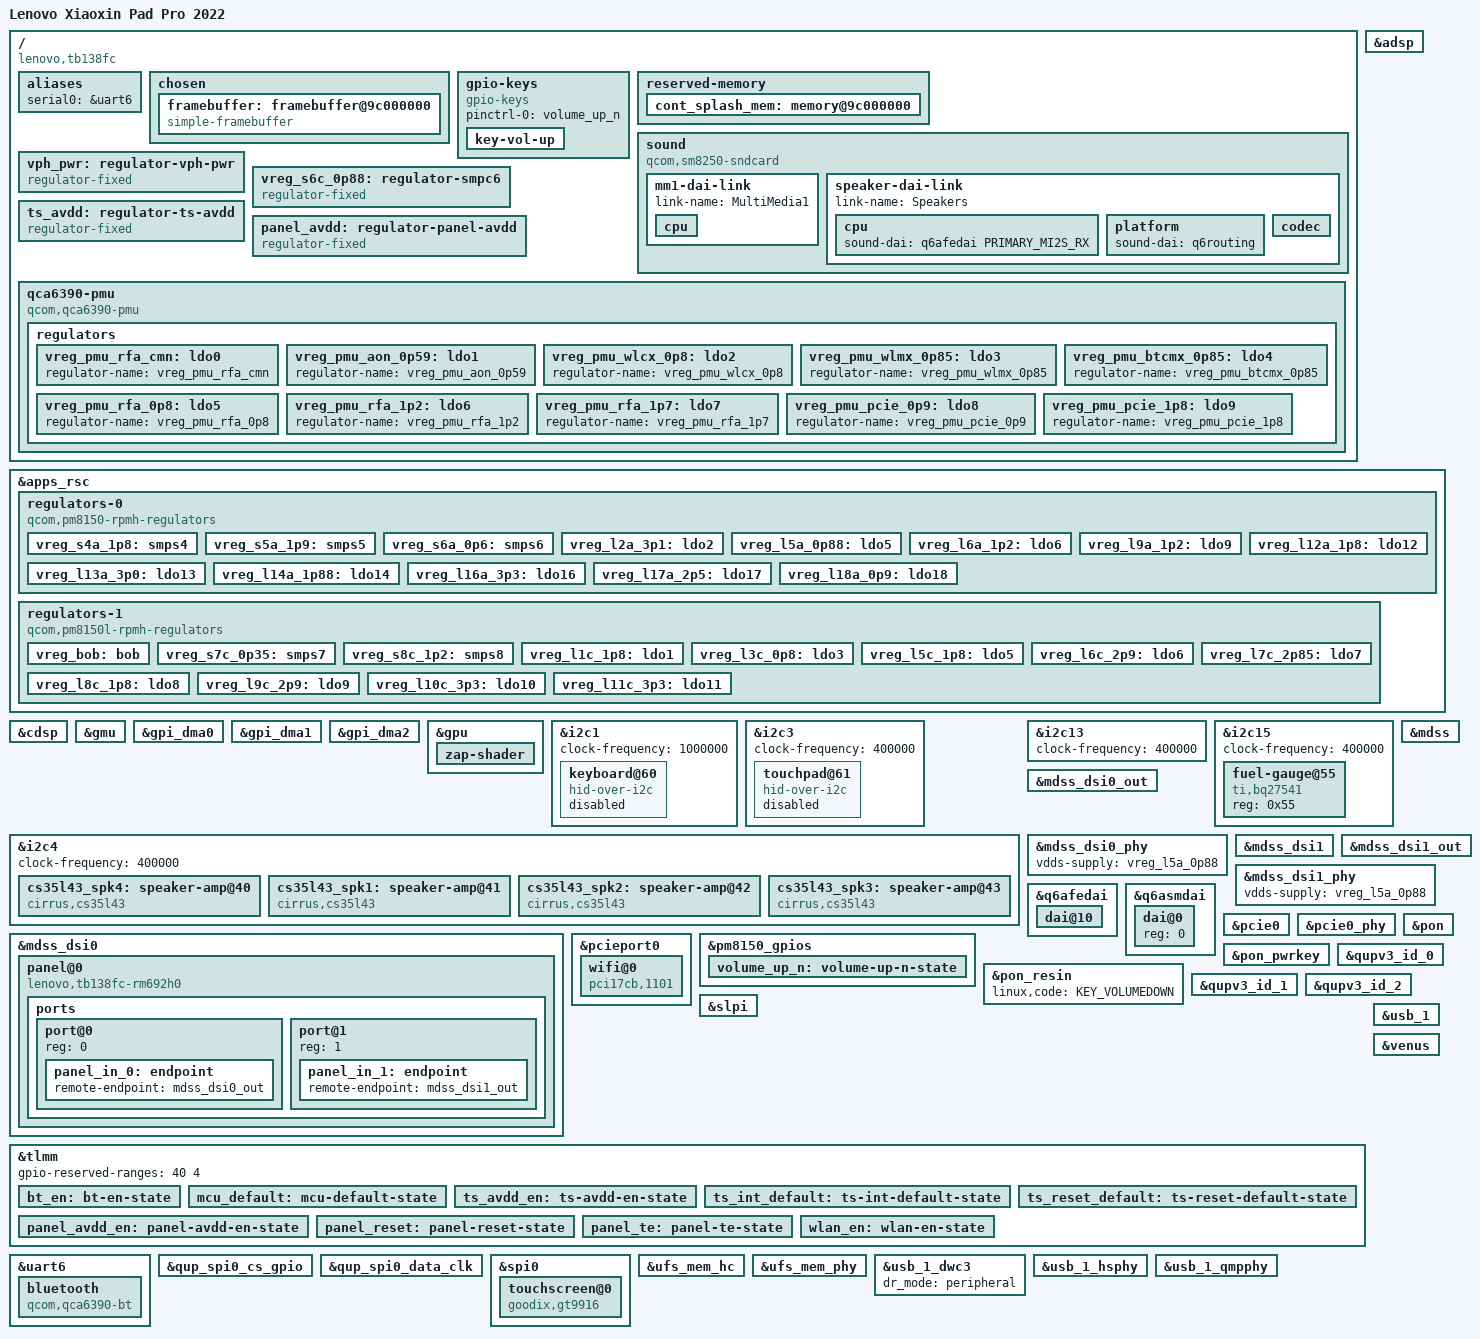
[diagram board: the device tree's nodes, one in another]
// SPDX-License-Identifier: GPL-2.0-only
/*
 * Copyright (c) 2025, David Wronek (sm8250-lenovo-j716f.dts)
 *
 * Lenovo Xiaoxin Pad Pro 2022 (TB138FC), derived from the J716F devicetree.
 * Initial bring-up: UFS, USB (peripheral), simple-framebuffer, buttons, fuel gauge.
 */

/dts-v1/;

#include <dt-bindings/arm/qcom,ids.h>
#include <dt-bindings/gpio/gpio.h>
#include <dt-bindings/phy/phy.h>
#include <dt-bindings/regulator/qcom,rpmh-regulator.h>
#include <dt-bindings/sound/qcom,q6afe.h>
#include <dt-bindings/sound/qcom,q6asm.h>
#include "sm8250.dtsi"
#include "pm8150.dtsi"
#include "pm8150l.dtsi"

/ {
	model = "Lenovo Xiaoxin Pad Pro 2022";
	compatible = "lenovo,tb138fc", "qcom,sm8250";
	chassis-type = "tablet";

	/* required for bootloader to select correct board */
	qcom,msm-id = <QCOM_ID_SM8250 0x20001>; /* SM8250 v2.1 */
	qcom,board-id = <0x10008 0>, <0x2010008 0>, <0x3010008 0>;

	aliases {
		serial0 = &uart6;
	};

	chosen {
		#address-cells = <2>;
		#size-cells = <2>;
		ranges;

		framebuffer: framebuffer@9c000000 {
			compatible = "simple-framebuffer";
			reg = <0x0 0x9c000000 0x0 0x2300000>;
			width = <2560>;
			height = <1536>;
			stride = <(2560 * 4)>;
			format = "a8r8g8b8";
		};
	};

	gpio-keys {
		compatible = "gpio-keys";

		pinctrl-names = "default";
		pinctrl-0 = <&volume_up_n>;

		key-vol-up {
			label = "Volume Up";
			linux,code = <KEY_VOLUMEUP>;
			gpios = <&pm8150_gpios 6 GPIO_ACTIVE_LOW>;
			debounce-interval = <15>;
			linux,can-disable;
			wakeup-source;
		};
	};

	reserved-memory {
		cont_splash_mem: memory@9c000000 {
			reg = <0x0 0x9c000000 0x0 0x2300000>;
			no-map;
		};
	};

	sound {
		compatible = "qcom,sm8250-sndcard";
		model = "Lenovo-TB138FC";
		pinctrl-0 = <&pri_mi2s_active>;
		pinctrl-names = "default";

		mm1-dai-link {
			link-name = "MultiMedia1";

			cpu {
				sound-dai = <&q6asmdai MSM_FRONTEND_DAI_MULTIMEDIA1>;
			};
		};

		speaker-dai-link {
			link-name = "Speakers";

			cpu {
				sound-dai = <&q6afedai PRIMARY_MI2S_RX>;
			};

			platform {
				sound-dai = <&q6routing>;
			};

			codec {
				sound-dai = <&cs35l43_spk1>, <&cs35l43_spk2>,
					    <&cs35l43_spk3>, <&cs35l43_spk4>;
			};
		};
	};

	vph_pwr: regulator-vph-pwr {
		compatible = "regulator-fixed";

		regulator-name = "vph_pwr";
		regulator-min-microvolt = <3700000>;
		regulator-max-microvolt = <3700000>;
		regulator-always-on;
		regulator-boot-on;
	};

	/* S6c is really ebi.lvl but it's there for supply map completeness sake. */
	vreg_s6c_0p88: regulator-smpc6 {
		compatible = "regulator-fixed";

		regulator-name = "vreg_s6c_0p88";
		regulator-min-microvolt = <880000>;
		regulator-max-microvolt = <880000>;
		regulator-always-on;

		vin-supply = <&vph_pwr>;
	};

	ts_avdd: regulator-ts-avdd {
		compatible = "regulator-fixed";
		regulator-name = "ts_avdd";
		regulator-min-microvolt = <3300000>;
		regulator-max-microvolt = <3300000>;

		gpio = <&tlmm 108 GPIO_ACTIVE_HIGH>;
		enable-active-high;
		startup-delay-us = <10000>;

		pinctrl-names = "default";
		pinctrl-0 = <&ts_avdd_en>;
	};

	panel_avdd: regulator-panel-avdd {
		compatible = "regulator-fixed";
		regulator-name = "panel_avdd";
		regulator-min-microvolt = <5500000>;
		regulator-max-microvolt = <5500000>;

		gpio = <&tlmm 61 GPIO_ACTIVE_HIGH>;
		enable-active-high;
		regulator-boot-on;

		pinctrl-names = "default";
		pinctrl-0 = <&panel_avdd_en>;
	};

	qca6390-pmu {
		compatible = "qcom,qca6390-pmu";

		pinctrl-names = "default";
		pinctrl-0 = <&bt_en>, <&wlan_en>;

		vddaon-supply = <&vreg_s6a_0p6>;
		vddpmu-supply = <&vreg_s6a_0p6>;
		vddrfa0p95-supply = <&vreg_s6a_0p6>;
		vddrfa1p3-supply = <&vreg_s8c_1p2>;
		vddrfa1p9-supply = <&vreg_s5a_1p9>;
		vddpcie1p3-supply = <&vreg_s8c_1p2>;
		vddpcie1p9-supply = <&vreg_s5a_1p9>;
		vddio-supply = <&vreg_s4a_1p8>;

		wlan-enable-gpios = <&tlmm 20 GPIO_ACTIVE_HIGH>;
		bt-enable-gpios = <&tlmm 21 GPIO_ACTIVE_HIGH>;

		regulators {
			vreg_pmu_rfa_cmn: ldo0 {
				regulator-name = "vreg_pmu_rfa_cmn";
			};

			vreg_pmu_aon_0p59: ldo1 {
				regulator-name = "vreg_pmu_aon_0p59";
			};

			vreg_pmu_wlcx_0p8: ldo2 {
				regulator-name = "vreg_pmu_wlcx_0p8";
			};

			vreg_pmu_wlmx_0p85: ldo3 {
				regulator-name = "vreg_pmu_wlmx_0p85";
			};

			vreg_pmu_btcmx_0p85: ldo4 {
				regulator-name = "vreg_pmu_btcmx_0p85";
			};

			vreg_pmu_rfa_0p8: ldo5 {
				regulator-name = "vreg_pmu_rfa_0p8";
			};

			vreg_pmu_rfa_1p2: ldo6 {
				regulator-name = "vreg_pmu_rfa_1p2";
			};

			vreg_pmu_rfa_1p7: ldo7 {
				regulator-name = "vreg_pmu_rfa_1p7";
			};

			vreg_pmu_pcie_0p9: ldo8 {
				regulator-name = "vreg_pmu_pcie_0p9";
			};

			vreg_pmu_pcie_1p8: ldo9 {
				regulator-name = "vreg_pmu_pcie_1p8";
			};
		};
	};
};

&adsp {
	firmware-name = "qcom/sm8250/LENOVO/TB138FC/adsp.mbn";
	status = "okay";
};

&apps_rsc {
	regulators-0 {
		compatible = "qcom,pm8150-rpmh-regulators";
		qcom,pmic-id = "a";

		vdd-s1-supply = <&vph_pwr>;
		vdd-s2-supply = <&vph_pwr>;
		vdd-s3-supply = <&vph_pwr>;
		vdd-s4-supply = <&vph_pwr>;
		vdd-s5-supply = <&vph_pwr>;
		vdd-s6-supply = <&vph_pwr>;
		vdd-s7-supply = <&vph_pwr>;
		vdd-s8-supply = <&vph_pwr>;
		vdd-s9-supply = <&vph_pwr>;
		vdd-s10-supply = <&vph_pwr>;
		vdd-l1-l8-l11-supply = <&vreg_s6c_0p88>;
		vdd-l2-l10-supply = <&vreg_bob>;
		vdd-l3-l4-l5-l18-supply = <&vreg_s6a_0p6>;
		vdd-l6-l9-supply = <&vreg_s8c_1p2>;
		vdd-l7-l12-l14-l15-supply = <&vreg_s5a_1p9>;
		vdd-l13-l16-l17-supply = <&vreg_bob>;

		/* (S1+S2+S3) - cx.lvl (ARC) */

		vreg_s4a_1p8: smps4 {
			regulator-name = "vreg_s4a_1p8";
			regulator-min-microvolt = <1800000>;
			regulator-max-microvolt = <1920000>;
			regulator-initial-mode = <RPMH_REGULATOR_MODE_HPM>;
			regulator-allow-set-load;
			regulator-allowed-modes = <RPMH_REGULATOR_MODE_LPM
						   RPMH_REGULATOR_MODE_HPM>;
		};

		vreg_s5a_1p9: smps5 {
			regulator-name = "vreg_s5a_1p9";
			regulator-min-microvolt = <1900000>;
			regulator-max-microvolt = <2040000>;
			regulator-initial-mode = <RPMH_REGULATOR_MODE_HPM>;
		};

		vreg_s6a_0p6: smps6 {
			regulator-name = "vreg_s6a_0p6";
			regulator-min-microvolt = <600000>;
			regulator-max-microvolt = <1128000>;
			regulator-initial-mode = <RPMH_REGULATOR_MODE_HPM>;
		};

		vreg_l2a_3p1: ldo2 {
			regulator-name = "vreg_l2a_3p1";
			regulator-min-microvolt = <3072000>;
			regulator-max-microvolt = <3072000>;
			regulator-initial-mode = <RPMH_REGULATOR_MODE_HPM>;
		};

		/* L3 is unused, L4 - lmx.lvl (ARC) */

		vreg_l5a_0p88: ldo5 {
			regulator-name = "vreg_l5a_0p88";
			regulator-min-microvolt = <880000>;
			regulator-max-microvolt = <880000>;
			regulator-initial-mode = <RPMH_REGULATOR_MODE_HPM>;
		};

		vreg_l6a_1p2: ldo6 {
			regulator-name = "vreg_l6a_1p2";
			regulator-min-microvolt = <1200000>;
			regulator-max-microvolt = <1200000>;
			regulator-initial-mode = <RPMH_REGULATOR_MODE_HPM>;
			regulator-allow-set-load;
			regulator-allowed-modes = <RPMH_REGULATOR_MODE_LPM
						   RPMH_REGULATOR_MODE_HPM>;
		};

		/* L7 is unused. */

		vreg_l9a_1p2: ldo9 {
			regulator-name = "vreg_l9a_1p2";
			regulator-min-microvolt = <1200000>;
			regulator-max-microvolt = <1200000>;
			regulator-initial-mode = <RPMH_REGULATOR_MODE_HPM>;
		};

		/* L10 is unused, L11 - lcx.lvl (ARC) */

		vreg_l12a_1p8: ldo12 {
			regulator-name = "vreg_l12a_1p8";
			regulator-min-microvolt = <1800000>;
			regulator-max-microvolt = <1800000>;
			regulator-initial-mode = <RPMH_REGULATOR_MODE_HPM>;
		};

		vreg_l13a_3p0: ldo13 {
			regulator-name = "vreg_l13a_3p0";
			regulator-min-microvolt = <3008000>;
			regulator-max-microvolt = <3008000>;
			regulator-initial-mode = <RPMH_REGULATOR_MODE_HPM>;
		};

		vreg_l14a_1p88: ldo14 {
			regulator-name = "vreg_l14a_1p88";
			regulator-min-microvolt = <1800000>;
			regulator-max-microvolt = <1880000>;
			regulator-initial-mode = <RPMH_REGULATOR_MODE_HPM>;
		};

		/* L15 is unused. */

		vreg_l16a_3p3: ldo16 {
			regulator-name = "vreg_l16a_3p3";
			regulator-min-microvolt = <3024000>;
			regulator-max-microvolt = <3304000>;
			regulator-initial-mode = <RPMH_REGULATOR_MODE_HPM>;
		};

		vreg_l17a_2p5: ldo17 {
			regulator-name = "vreg_l17a_2p5";
			regulator-min-microvolt = <2496000>;
			regulator-max-microvolt = <3008000>;
			regulator-initial-mode = <RPMH_REGULATOR_MODE_HPM>;
			regulator-allow-set-load;
			regulator-allowed-modes = <RPMH_REGULATOR_MODE_LPM
						   RPMH_REGULATOR_MODE_HPM>;
		};

		vreg_l18a_0p9: ldo18 {
			regulator-name = "vreg_l18a_0p9";
			regulator-min-microvolt = <800000>;
			regulator-max-microvolt = <920000>;
			regulator-initial-mode = <RPMH_REGULATOR_MODE_HPM>;
		};
	};

	/*
	 * Remaining regulators that are not yet supported:
	 * OLEDB: 4925000-8100000
	 * ab: 4600000-6100000
	 * ibb: 800000-5400000
	 */

	regulators-1 {
		compatible = "qcom,pm8150l-rpmh-regulators";
		qcom,pmic-id = "c";

		vdd-s1-supply = <&vph_pwr>;
		vdd-s2-supply = <&vph_pwr>;
		vdd-s3-supply = <&vph_pwr>;
		vdd-s4-supply = <&vph_pwr>;
		vdd-s5-supply = <&vph_pwr>;
		vdd-s6-supply = <&vph_pwr>;
		vdd-s7-supply = <&vph_pwr>;
		vdd-s8-supply = <&vph_pwr>;
		vdd-l1-l8-supply = <&vreg_s4a_1p8>;
		vdd-l2-l3-supply = <&vreg_s8c_1p2>;
		vdd-l4-l5-l6-supply = <&vreg_bob>;
		vdd-l7-l11-supply = <&vreg_bob>;
		vdd-l9-l10-supply = <&vreg_bob>;
		vdd-bob-supply = <&vph_pwr>;

		vreg_bob: bob {
			regulator-name = "vreg_bob";
			regulator-min-microvolt = <3008000>;
			regulator-max-microvolt = <3960000>;
			regulator-initial-mode = <RPMH_REGULATOR_MODE_AUTO>;
		};

		/*
		 * S1-S6 are ARCs:
		 * (S1+S2) - gfx.lvl,
		 * S3 - mx.lvl,
		 * (S4+S5) - mmcx.lvl,
		 * S6 - ebi.lvl
		 */

		vreg_s7c_0p35: smps7 {
			regulator-name = "vreg_s7c_0p35";
			regulator-min-microvolt = <348000>;
			regulator-max-microvolt = <1000000>;
			regulator-initial-mode = <RPMH_REGULATOR_MODE_HPM>;
		};

		vreg_s8c_1p2: smps8 {
			regulator-name = "vreg_s8c_1p2";
			regulator-min-microvolt = <1200000>;
			regulator-max-microvolt = <1400000>;
			regulator-initial-mode = <RPMH_REGULATOR_MODE_HPM>;
		};

		vreg_l1c_1p8: ldo1 {
			regulator-name = "vreg_l1c_1p8";
			regulator-min-microvolt = <1800000>;
			regulator-max-microvolt = <1800000>;
			regulator-initial-mode = <RPMH_REGULATOR_MODE_HPM>;
		};

		/* L2 is unused. */

		vreg_l3c_0p8: ldo3 {
			regulator-name = "vreg_l3c_0p8";
			regulator-min-microvolt = <800000>;
			regulator-max-microvolt = <1200000>;
			regulator-initial-mode = <RPMH_REGULATOR_MODE_HPM>;
		};

		/* L4 is unused. */

		vreg_l5c_1p8: ldo5 {
			regulator-name = "vreg_l5c_1p8";
			regulator-min-microvolt = <1800000>;
			regulator-max-microvolt = <2800000>;
			regulator-initial-mode = <RPMH_REGULATOR_MODE_HPM>;
		};

		vreg_l6c_2p9: ldo6 {
			regulator-name = "vreg_l6c_2p9";
			regulator-min-microvolt = <1800000>;
			regulator-max-microvolt = <2960000>;
			regulator-initial-mode = <RPMH_REGULATOR_MODE_HPM>;
			regulator-allow-set-load;
			regulator-allowed-modes = <RPMH_REGULATOR_MODE_LPM
						   RPMH_REGULATOR_MODE_HPM>;
		};

		vreg_l7c_2p85: ldo7 {
			regulator-name = "vreg_l7c_2p85";
			regulator-min-microvolt = <2856000>;
			regulator-max-microvolt = <3104000>;
			regulator-initial-mode = <RPMH_REGULATOR_MODE_HPM>;
		};

		vreg_l8c_1p8: ldo8 {
			regulator-name = "vreg_l8c_1p8";
			regulator-min-microvolt = <1800000>;
			regulator-max-microvolt = <1800000>;
			regulator-initial-mode = <RPMH_REGULATOR_MODE_HPM>;
		};

		vreg_l9c_2p9: ldo9 {
			regulator-name = "vreg_l9c_2p9";
			regulator-min-microvolt = <2704000>;
			regulator-max-microvolt = <2960000>;
			regulator-initial-mode = <RPMH_REGULATOR_MODE_HPM>;
			regulator-allow-set-load;
			regulator-allowed-modes = <RPMH_REGULATOR_MODE_LPM
						   RPMH_REGULATOR_MODE_HPM>;
		};

		vreg_l10c_3p3: ldo10 {
			regulator-name = "vreg_l10c_3p3";
			regulator-min-microvolt = <3000000>;
			regulator-max-microvolt = <3312000>;
			regulator-initial-mode = <RPMH_REGULATOR_MODE_HPM>;
		};

		vreg_l11c_3p3: ldo11 {
			regulator-name = "vreg_l11c_3p3";
			regulator-min-microvolt = <3300000>;	/* panel vdd: stock 3.3 V */
			regulator-max-microvolt = <3304000>;
			regulator-initial-mode = <RPMH_REGULATOR_MODE_HPM>;
		};
	};

};

&cdsp {
	firmware-name = "qcom/sm8250/LENOVO/TB138FC/cdsp.mbn";
	status = "okay";
};

&gmu {
	status = "okay";
};

&gpi_dma0 {
	status = "okay";
};

&gpi_dma1 {
	status = "okay";
};

&gpi_dma2 {
	status = "okay";
};

&gpu {
	status = "okay";

	zap-shader {
		memory-region = <&gpu_mem>;
		firmware-name = "qcom/sm8250/LENOVO/TB138FC/a650_zap.mbn";
	};
};

&i2c1 {
	clock-frequency = <1000000>;
	status = "okay";

	/* Stock: keyboard@60, irqs on gpio54/gpio129; not yet verified */
	keyboard@60 {
		compatible = "hid-over-i2c";
		reg = <0x60>;

		vdd-supply = <&vreg_l16a_3p3>;
		vddl-supply = <&vreg_l8c_1p8>;

		interrupt-parent = <&tlmm>;
		interrupts = <54 IRQ_TYPE_LEVEL_LOW>;

		hid-descr-addr = <0x01>;
		post-power-on-delay-ms = <100>;
		status = "disabled";
	};
};

&i2c3 {
	clock-frequency = <400000>;
	status = "okay";

	/* Stock: keyboard-pack touchpad, irq on gpio11; not yet verified */
	touchpad@61 {
		compatible = "hid-over-i2c";
		reg = <0x61>;

		vdd-supply = <&vreg_l16a_3p3>;
		vddl-supply = <&vreg_l8c_1p8>;

		pinctrl-names = "default";
		pinctrl-0 = <&mcu_default>;

		interrupt-parent = <&tlmm>;
		interrupts = <11 IRQ_TYPE_LEVEL_LOW>;

		hid-descr-addr = <0x01>;
		post-power-on-delay-ms = <100>;
		status = "disabled";
	};
};

&i2c4 {
	clock-frequency = <400000>;
	status = "okay";


	cs35l43_spk4: speaker-amp@40 {
		compatible = "cirrus,cs35l43";
		reg = <0x40>;
		interrupts-extended = <&tlmm 68 IRQ_TYPE_LEVEL_LOW>;
		reset-gpios = <&tlmm 131 GPIO_ACTIVE_HIGH>;
		VA-supply = <&vreg_s4a_1p8>;
		VP-supply = <&vph_pwr>;
		#sound-dai-cells = <0>;
		sound-name-prefix = "SPK4";
		cirrus,dsp-part-name = "spk4-cs35l43";
		cirrus,bst-ipk-ma = <3200>;	/* stock boost-peak-milliamp */
		cirrus,asp-sdout-hiz = <3>;
		cirrus,vpbr-enable = <1>;
		cirrus,vpbr-atk-vol = <2>;
		cirrus,vpbr-max-att = <6>;
		cirrus,vpbr-thld = <21>;
	};

	cs35l43_spk1: speaker-amp@41 {
		compatible = "cirrus,cs35l43";
		reg = <0x41>;
		interrupts-extended = <&tlmm 68 IRQ_TYPE_LEVEL_LOW>;
		reset-gpios = <&tlmm 131 GPIO_ACTIVE_HIGH>;
		VA-supply = <&vreg_s4a_1p8>;
		VP-supply = <&vph_pwr>;
		#sound-dai-cells = <0>;
		sound-name-prefix = "SPK1";
		cirrus,dsp-part-name = "spk1-cs35l43";
		cirrus,bst-ipk-ma = <3200>;	/* stock boost-peak-milliamp */
		cirrus,asp-sdout-hiz = <3>;
		cirrus,vpbr-enable = <1>;
		cirrus,vpbr-atk-vol = <2>;
		cirrus,vpbr-max-att = <6>;
		cirrus,vpbr-thld = <21>;
	};

	cs35l43_spk2: speaker-amp@42 {
		compatible = "cirrus,cs35l43";
		reg = <0x42>;
		interrupts-extended = <&tlmm 68 IRQ_TYPE_LEVEL_LOW>;
		reset-gpios = <&tlmm 131 GPIO_ACTIVE_HIGH>;
		VA-supply = <&vreg_s4a_1p8>;
		VP-supply = <&vph_pwr>;
		#sound-dai-cells = <0>;
		sound-name-prefix = "SPK2";
		cirrus,dsp-part-name = "spk2-cs35l43";
		cirrus,bst-ipk-ma = <3200>;	/* stock boost-peak-milliamp */
		cirrus,asp-sdout-hiz = <3>;
		cirrus,vpbr-enable = <1>;
		cirrus,vpbr-atk-vol = <2>;
		cirrus,vpbr-max-att = <6>;
		cirrus,vpbr-thld = <21>;
	};

	cs35l43_spk3: speaker-amp@43 {
		compatible = "cirrus,cs35l43";
		reg = <0x43>;
		interrupts-extended = <&tlmm 68 IRQ_TYPE_LEVEL_LOW>;
		reset-gpios = <&tlmm 131 GPIO_ACTIVE_HIGH>;
		VA-supply = <&vreg_s4a_1p8>;
		VP-supply = <&vph_pwr>;
		#sound-dai-cells = <0>;
		sound-name-prefix = "SPK3";
		cirrus,dsp-part-name = "spk3-cs35l43";
		cirrus,bst-ipk-ma = <3200>;	/* stock boost-peak-milliamp */
		cirrus,asp-sdout-hiz = <3>;
		cirrus,vpbr-enable = <1>;
		cirrus,vpbr-atk-vol = <2>;
		cirrus,vpbr-max-att = <6>;
		cirrus,vpbr-thld = <21>;
	};
};

&i2c13 {
	clock-frequency = <400000>;
	status = "okay";

	/* onsemi USB redriver @ 19 */
	/* NXP CTN730 @ 28 */
};

&i2c15 {
	clock-frequency = <400000>;
	status = "okay";

	/* Qcom SMB1396 @ 34, SMB1396 slave @ 35, SMB1398 @ 36 */

	/* Stock overlay lists bq27541 on both se3 and se15; it NACKs on i2c3, and lenovo-q706f uses i2c15 */
	fuel-gauge@55 {
		compatible = "ti,bq27541";
		reg = <0x55>;
	};
};

&mdss {
	status = "okay";
};

&mdss_dsi0 {
	vdda-supply = <&vreg_l9a_1p2>;
	qcom,dual-dsi-mode;
	/* with kernel/patches/0001: DCS sent on DSI0 is broadcast to both links */
	qcom,sync-dual-dsi;
	qcom,master-dsi;
	status = "okay";

	panel@0 {
		compatible = "lenovo,tb138fc-rm692h0";
		reg = <0>;

		vddio-supply = <&vreg_l14a_1p88>;
		vdd-supply = <&vreg_l11c_3p3>;
		avdd-supply = <&panel_avdd>;
		reset-gpios = <&tlmm 75 GPIO_ACTIVE_LOW>;

		pinctrl-names = "default";
		pinctrl-0 = <&panel_reset>, <&panel_te>;

		ports {
			#address-cells = <1>;
			#size-cells = <0>;

			port@0 {
				reg = <0>;

				panel_in_0: endpoint {
					remote-endpoint = <&mdss_dsi0_out>;
				};
			};

			port@1 {
				reg = <1>;

				panel_in_1: endpoint {
					remote-endpoint = <&mdss_dsi1_out>;
				};
			};
		};
	};
};

&mdss_dsi0_out {
	data-lanes = <0 1 2 3>;
	remote-endpoint = <&panel_in_0>;
};

&mdss_dsi0_phy {
	vdds-supply = <&vreg_l5a_0p88>;
	status = "okay";
};

&mdss_dsi1 {
	vdda-supply = <&vreg_l9a_1p2>;
	qcom,dual-dsi-mode;
	qcom,sync-dual-dsi;
	/* bonded mode: msm itself slaves this PHY to DSI0's PLL (as on J716F) */
	status = "okay";
};

&mdss_dsi1_out {
	data-lanes = <0 1 2 3>;
	remote-endpoint = <&panel_in_1>;
};

&mdss_dsi1_phy {
	vdds-supply = <&vreg_l5a_0p88>;
	status = "okay";
};

&q6afedai {
	dai@10 {
		reg = <PRIMARY_MI2S_RX>;
		qcom,sd-lines = <1>;
	};
};

&q6asmdai {
	dai@0 {
		reg = <0>;
	};
};

&pcie0 {
	status = "okay";
};

&pcie0_phy {
	vdda-phy-supply = <&vreg_l5a_0p88>;
	vdda-pll-supply = <&vreg_l9a_1p2>;
	status = "okay";
};

&pcieport0 {
	wifi@0 {
		compatible = "pci17cb,1101";
		reg = <0x10000 0x0 0x0 0x0 0x0>;

		vddrfacmn-supply = <&vreg_pmu_rfa_cmn>;
		vddaon-supply = <&vreg_pmu_aon_0p59>;
		vddwlcx-supply = <&vreg_pmu_wlcx_0p8>;
		vddwlmx-supply = <&vreg_pmu_wlmx_0p85>;
		vddrfa0p8-supply = <&vreg_pmu_rfa_0p8>;
		vddrfa1p2-supply = <&vreg_pmu_rfa_1p2>;
		vddrfa1p7-supply = <&vreg_pmu_rfa_1p7>;
		vddpcie0p9-supply = <&vreg_pmu_pcie_0p9>;
		vddpcie1p8-supply = <&vreg_pmu_pcie_1p8>;
	};
};

&pm8150_gpios {
	volume_up_n: volume-up-n-state {
		pins = "gpio6";
		function = "normal";
		bias-pull-up;
		input-enable;
		power-source = <1>;
	};
};

&pon {
	mode-bootloader = <0x2>;
	mode-recovery = <0x1>;
};

&pon_pwrkey {
	status = "okay";
};

&pon_resin {
	linux,code = <KEY_VOLUMEDOWN>;
	status = "okay";
};

&qupv3_id_0 {
	status = "okay";
};

&qupv3_id_1 {
	status = "okay";
};

&qupv3_id_2 {
	status = "okay";
};

&slpi {
	firmware-name = "qcom/sm8250/LENOVO/TB138FC/slpi.mbn";
	status = "okay";
};

&tlmm {
	gpio-reserved-ranges = <40 4>;

	bt_en: bt-en-state {
		pins = "gpio21";
		function = "gpio";
		drive-strength = <16>;
		output-low;
		bias-pull-up;
	};

	mcu_default: mcu-default-state {
		pins = "gpio11", "gpio14", "gpio25";
		function = "gpio";
		bias-disable;
	};

	ts_avdd_en: ts-avdd-en-state {
		pins = "gpio108";
		function = "gpio";
		drive-strength = <2>;
		bias-disable;
	};

	ts_int_default: ts-int-default-state {
		pins = "gpio39";
		function = "gpio";
		drive-strength = <2>;
		bias-pull-up;
		input-enable;
	};

	ts_reset_default: ts-reset-default-state {
		pins = "gpio38";
		function = "gpio";
		drive-strength = <2>;
		bias-disable;
	};

	panel_avdd_en: panel-avdd-en-state {
		pins = "gpio61";
		function = "gpio";
		drive-strength = <8>;
		bias-disable;
	};

	panel_reset: panel-reset-state {
		pins = "gpio75";
		function = "gpio";
		drive-strength = <8>;
		bias-disable;
	};

	panel_te: panel-te-state {
		pins = "gpio66", "gpio67";
		function = "mdp_vsync";
		drive-strength = <2>;
		bias-pull-down;
	};

	wlan_en: wlan-en-state {
		pins = "gpio20";
		function = "gpio";
		drive-strength = <16>;
		output-low;
		bias-pull-up;
	};
};

&uart6 {
	status = "okay";

	bluetooth {
		compatible = "qcom,qca6390-bt";

		vddrfacmn-supply = <&vreg_pmu_rfa_cmn>;
		vddaon-supply = <&vreg_pmu_aon_0p59>;
		vddbtcmx-supply = <&vreg_pmu_btcmx_0p85>;
		vddrfa0p8-supply = <&vreg_pmu_rfa_0p8>;
		vddrfa1p2-supply = <&vreg_pmu_rfa_1p2>;
		vddrfa1p7-supply = <&vreg_pmu_rfa_1p7>;
	};
};

&qup_spi0_cs_gpio {
	drive-strength = <6>;
	bias-disable;
};

&qup_spi0_data_clk {
	drive-strength = <6>;
	bias-disable;
};

&spi0 {
	/* GPIO chip-select keeps CS asserted across the Berlin write+read (as on lenovo-q706f) */
	pinctrl-names = "default";
	pinctrl-0 = <&qup_spi0_data_clk>, <&qup_spi0_cs_gpio>;
	cs-gpios = <&tlmm 31 GPIO_ACTIVE_LOW>;
	status = "okay";

	touchscreen@0 {
		compatible = "goodix,gt9916";
		reg = <0>;
		spi-max-frequency = <1000000>;

		interrupts-extended = <&tlmm 39 IRQ_TYPE_EDGE_FALLING>;
		reset-gpios = <&tlmm 38 GPIO_ACTIVE_LOW>;
		avdd-supply = <&ts_avdd>;

		pinctrl-names = "default";
		pinctrl-0 = <&ts_int_default>, <&ts_reset_default>;

		touchscreen-size-x = <2560>;
		touchscreen-size-y = <1536>;
	};
};

&ufs_mem_hc {
	vcc-supply = <&vreg_l17a_2p5>;
	vcc-max-microamp = <800000>;
	vccq-supply = <&vreg_l6a_1p2>;
	vccq-max-microamp = <800000>;
	vccq2-supply = <&vreg_s4a_1p8>;
	vccq2-max-microamp = <800000>;

	status = "okay";
};

&ufs_mem_phy {
	vdda-phy-supply = <&vreg_l5a_0p88>;
	vdda-pll-supply = <&vreg_l9a_1p2>;

	status = "okay";
};

&usb_1 {
	status = "okay";
};

&usb_1_dwc3 {
	dr_mode = "peripheral";
};

&usb_1_hsphy {
	vdda-pll-supply = <&vreg_l5a_0p88>;
	vdda18-supply = <&vreg_l12a_1p8>;
	vdda33-supply = <&vreg_l2a_3p1>;

	status = "okay";
};

&usb_1_qmpphy {
	vdda-phy-supply = <&vreg_l9a_1p2>;
	vdda-pll-supply = <&vreg_l18a_0p9>;

	status = "okay";
};

&venus {
	firmware-name = "qcom/sm8250/LENOVO/TB138FC/venus.mbn";
	status = "okay";
};
